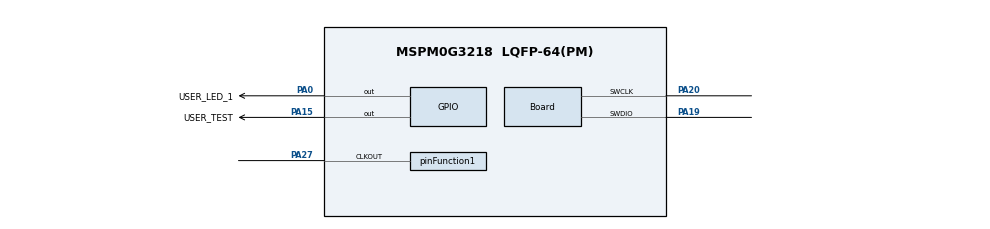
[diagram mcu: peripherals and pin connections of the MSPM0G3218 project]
//@cliArgs --device "MSPM0G321X" --package "LQFP-64(PM)" --part "Default"
//@v2CliArgs --device "MSPM0G3218" --package "LQFP-64(PM)"
// @cliArgs --board /ti/boards/LP_MSPM0G3218 --rtos nortos

/**
 * Import the modules used in this configuration.
 */
const GPIO   = scripting.addModule("/ti/driverlib/GPIO", {}, false);
const GPIO1  = GPIO.addInstance();
const SYSCTL = scripting.addModule("/ti/driverlib/SYSCTL");
const TIMER  = scripting.addModule("/ti/driverlib/TIMER", {}, false);
const TIMER1 = TIMER.addInstance();

/**
 * Write custom configuration values to the imported modules.
 */
const gate7  = system.clockTree["MFCLKGATE"];
gate7.enable = true;

const pinFunction1                        = system.clockTree["CLKOUT"];
pinFunction1.enable                       = true;
pinFunction1.peripheral.$assign           = "SYSCTL";
pinFunction1.peripheral.clkOutPin.$assign = "PA27";

GPIO1.$name                          = "GPIO_LEDS";
GPIO1.associatedPins.create(2);
GPIO1.associatedPins[0].$name        = "USER_LED_1";
GPIO1.associatedPins[0].assignedPort = "PORTA";
GPIO1.associatedPins[0].assignedPin  = "0";
GPIO1.associatedPins[0].initialValue = "SET";
GPIO1.associatedPins[0].pin.$assign  = "PA0";
GPIO1.associatedPins[1].$name        = "USER_TEST";
GPIO1.associatedPins[1].assignedPort = "PORTA";
GPIO1.associatedPins[1].assignedPin  = "15";
GPIO1.associatedPins[1].initialValue = "SET";
GPIO1.associatedPins[1].pin.$assign  = "PA15";

const Board                       = scripting.addModule("/ti/driverlib/Board", {}, false);
Board.configureUnused             = true;
Board.peripheral.$assign          = "DEBUGSS";
Board.peripheral.swclkPin.$assign = "PA20";
Board.peripheral.swdioPin.$assign = "PA19";

SYSCTL.powerPolicy           = "STOP0";
SYSCTL.forceDefaultClkConfig = true;
SYSCTL.clockTreeEn           = true;

TIMER1.$name              = "TIMER_0";
TIMER1.timerMode          = "PERIODIC";
TIMER1.timerPeriod        = "500 ms";
TIMER1.interrupts         = ["ZERO"];
TIMER1.timerClkSrc        = "MFCLK";
TIMER1.timerClkPrescale   = 256;
TIMER1.peripheral.$assign = "TIMG0";

const ProjectConfig              = scripting.addModule("/ti/project_config/ProjectConfig", {}, false);
ProjectConfig.migrationCondition = true;
